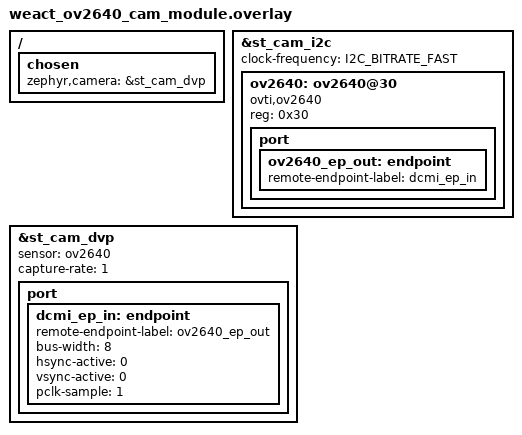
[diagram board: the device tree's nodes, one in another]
/*
 * Copyright (c) 2024 Charles Dias
 *
 * SPDX-License-Identifier: Apache-2.0
 */

/ {
	chosen {
		zephyr,camera = &st_cam_dvp;
	};
};

&st_cam_i2c {
	status = "okay";
	clock-frequency = <I2C_BITRATE_FAST>;

	ov2640: ov2640@30 {
		compatible = "ovti,ov2640";
		reg = <0x30>;
		status = "okay";

		port {
			ov2640_ep_out: endpoint {
				remote-endpoint-label = "dcmi_ep_in";
			};
		};
	};
};

&st_cam_dvp {
	status = "okay";
	sensor = <&ov2640>;
	capture-rate = <1>;

	port {
		dcmi_ep_in: endpoint {
			remote-endpoint-label = "ov2640_ep_out";
			bus-width = <8>;
			hsync-active = <0>;
			vsync-active = <0>;
			pclk-sample = <1>;
		};
	};
};
